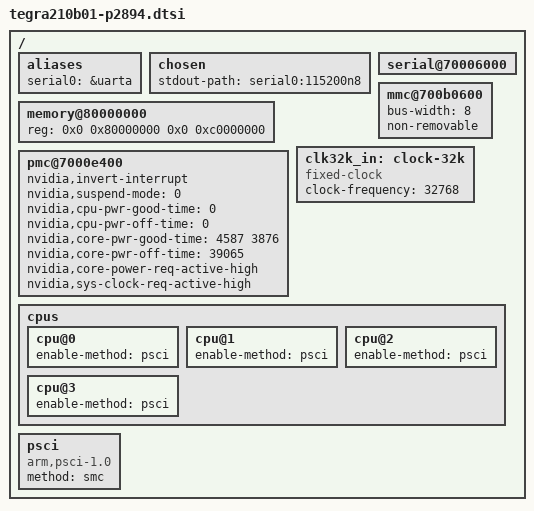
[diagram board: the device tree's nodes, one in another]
// SPDX-License-Identifier: GPL-2.0
#include "tegra210b01.dtsi"

/ {
	aliases {
		serial0 = &uarta;
	};

	chosen {
		stdout-path = "serial0:115200n8";
	};

	memory@80000000 {
		device_type = "memory";
		reg = <0x0 0x80000000 0x0 0xc0000000>;
	};

	serial@70006000 {
		/delete-property/ dmas;
		/delete-property/ dma-names;
		status = "okay";
	};

	pmc@7000e400 {
		nvidia,invert-interrupt;
		nvidia,suspend-mode = <0>;
		nvidia,cpu-pwr-good-time = <0>;
		nvidia,cpu-pwr-off-time = <0>;
		nvidia,core-pwr-good-time = <4587 3876>;
		nvidia,core-pwr-off-time = <39065>;
		nvidia,core-power-req-active-high;
		nvidia,sys-clock-req-active-high;
		status = "okay";
	};

	mmc@700b0600 {
		bus-width = <8>;
		non-removable;
		status = "okay";
	};

	clk32k_in: clock-32k {
		compatible = "fixed-clock";
		clock-frequency = <32768>;
		#clock-cells = <0>;
	};

	cpus {
		cpu@0 {
			enable-method = "psci";
		};

		cpu@1 {
			enable-method = "psci";
		};

		cpu@2 {
			enable-method = "psci";
		};

		cpu@3 {
			enable-method = "psci";
		};
	};

	psci {
		compatible = "arm,psci-1.0";
		method = "smc";
	};
};
